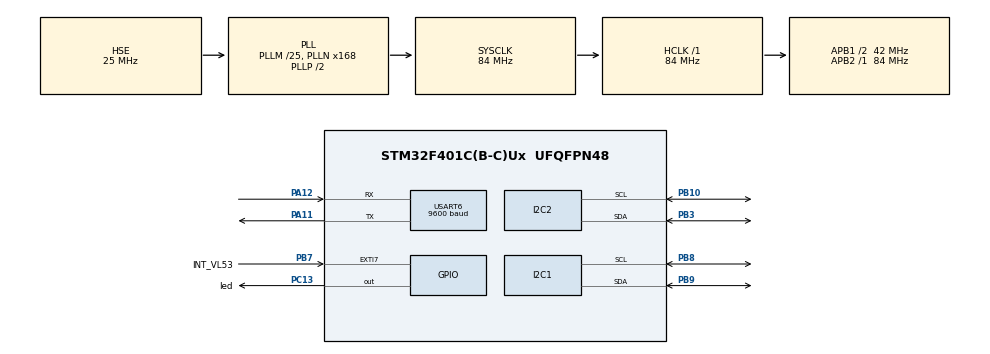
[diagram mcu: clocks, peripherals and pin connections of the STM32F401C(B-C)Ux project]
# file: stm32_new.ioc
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Dma.Request0=USART6_RX
Dma.Request1=USART6_TX
Dma.USART6_RX.0.Direction=DMA_PERIPH_TO_MEMORY
Dma.USART6_RX.0.FIFOMode=DMA_FIFOMODE_DISABLE
Dma.USART6_RX.0.Instance=DMA2_Stream1
Dma.USART6_RX.0.MemDataAlignment=DMA_MDATAALIGN_BYTE
Dma.USART6_RX.0.MemInc=DMA_MINC_ENABLE
Dma.USART6_RX.0.Mode=DMA_NORMAL
Dma.USART6_RX.0.PeriphDataAlignment=DMA_PDATAALIGN_BYTE
Dma.USART6_RX.0.PeriphInc=DMA_PINC_DISABLE
Dma.USART6_RX.0.Priority=DMA_PRIORITY_LOW
Dma.USART6_TX.1.Direction=DMA_MEMORY_TO_PERIPH
Dma.USART6_TX.1.FIFOMode=DMA_FIFOMODE_DISABLE
Dma.USART6_TX.1.Instance=DMA2_Stream6
Dma.USART6_TX.1.MemDataAlignment=DMA_MDATAALIGN_BYTE
Dma.USART6_TX.1.MemInc=DMA_MINC_ENABLE
Dma.USART6_TX.1.Mode=DMA_NORMAL
Dma.USART6_TX.1.PeriphDataAlignment=DMA_PDATAALIGN_BYTE
Dma.USART6_TX.1.PeriphInc=DMA_PINC_DISABLE
Dma.USART6_TX.1.Priority=DMA_PRIORITY_LOW
FREERTOS.Tasks01=VL53_T,24,256,VL53_F,Default,NULL,Dynamic,NULL,NULL;PLC_T,8,256,PLC_F,Default,NULL,Dynamic,NULL,NULL;OLED096_T,8,256,OLED096_F,Default,NULL,Dynamic,NULL,NULL
FREERTOS.configENABLE_FPU=1
FREERTOS.configUSE_NEWLIB_REENTRANT=1
I2C2.I2C_Mode=I2C_Fast
Mcu.Family=STM32F4
Mcu.Name=STM32F401C(B-C)Ux
Mcu.Package=UFQFPN48
NVIC.DMA2_Stream1_IRQn=true\:5\:0\:false\:false\:true\:true\:false\:true\:true
NVIC.DMA2_Stream6_IRQn=true\:5\:0\:false\:false\:true\:true\:false\:true\:true
NVIC.EXTI9_5_IRQn=true\:5\:0\:false\:false\:true\:false\:true\:true\:true
NVIC.PriorityGroup=NVIC_PRIORITYGROUP_4
NVIC.TIM1_BRK_TIM9_IRQn=true\:15\:0\:false\:false\:true\:false\:false\:true\:true
NVIC.TimeBase=TIM1_BRK_TIM9_IRQn
NVIC.TimeBaseIP=TIM9
NVIC.USART6_IRQn=true\:5\:0\:false\:false\:true\:true\:false\:true\:true
PA11.Mode=Asynchronous
PA11.Signal=USART6_TX
PA12.Mode=Asynchronous
PA12.Signal=USART6_RX
PA13.Mode=Serial_Wire
PA13.Signal=SYS_JTMS-SWDIO
PA14.Mode=Serial_Wire
PA14.Signal=SYS_JTCK-SWCLK
PB10.GPIO_Pu=GPIO_PULLUP
PB10.Mode=I2C
PB10.Signal=I2C2_SCL
PB3.GPIO_Pu=GPIO_PULLUP
PB3.Mode=I2C
PB3.Signal=I2C2_SDA
PB7.GPIO_Label=INT_VL53
PB7.GPIO_ModeDefaultEXTI=GPIO_MODE_IT_FALLING
PB7.GPIO_PuPd=GPIO_PULLUP
PB7.Signal=GPXTI7
PB8.Mode=I2C
PB8.Signal=I2C1_SCL
PB9.Mode=I2C
PB9.Signal=I2C1_SDA
PC13-ANTI_TAMP.GPIO_Label=led
PC13-ANTI_TAMP.Signal=GPIO_Output
PH0\ -\ OSC_IN.Mode=HSE-External-Oscillator
PH0\ -\ OSC_IN.Signal=RCC_OSC_IN
PH1\ -\ OSC_OUT.Mode=HSE-External-Oscillator
PH1\ -\ OSC_OUT.Signal=RCC_OSC_OUT
ProjectManager.HeapSize=0x200
ProjectManager.StackSize=0x400
ProjectManager.TargetToolchain=STM32CubeIDE
RCC.48MHZClocksFreq_Value=42000000
RCC.AHBFreq_Value=84000000
RCC.APB1CLKDivider=RCC_HCLK_DIV2
RCC.APB1Freq_Value=42000000
RCC.APB1TimFreq_Value=84000000
RCC.APB2Freq_Value=84000000
RCC.APB2TimFreq_Value=84000000
RCC.CortexFreq_Value=84000000
RCC.HCLKFreq_Value=84000000
RCC.HSE_VALUE=25000000
RCC.HSI_VALUE=16000000
RCC.LSE_VALUE=32768
RCC.PLLM=25
RCC.PLLN=168
RCC.PLLSourceVirtual=RCC_PLLSOURCE_HSE
RCC.SYSCLKFreq_VALUE=84000000
RCC.SYSCLKSource=RCC_SYSCLKSOURCE_PLLCLK
RCC.VCOOutputFreq_Value=168000000
USART6.BaudRate=9600
USART6.OverSampling=UART_OVERSAMPLING_16
USART6.Parity=PARITY_ODD
USART6.VirtualMode=VM_ASYNC
USART6.WordLength=WORDLENGTH_9B
VP_FREERTOS_VS_CMSIS_V2.Mode=CMSIS_V2
VP_SYS_VS_tim9.Mode=TIM9
board=custom

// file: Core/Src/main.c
/* USER CODE BEGIN Header */
/**
  ******************************************************************************
  * @file           : main.c
  * @brief          : Main program body
  ******************************************************************************
  * @attention
  *
  * Copyright (c) 2026 STMicroelectronics.
  * All rights reserved.
  *
  * This software is licensed under terms that can be found in the LICENSE file
  * in the root directory of this software component.
  * If no LICENSE file comes with this software, it is provided AS-IS.
  *
  ******************************************************************************
  */
/* USER CODE END Header */
#include "main.h"
#include "cmsis_os.h"
#include "dma.h"
#include "i2c.h"
#include "usart.h"
#include "gpio.h"

/* USER CODE BEGIN Includes */
#include "VL53L.h"
/* USER CODE END Includes */

void SystemClock_Config(void);
void MX_FREERTOS_Init(void);

int main(void)
{

  /* MCU Configuration--------------------------------------------------------*/

  /* Reset of all peripherals, Initializes the Flash interface and the Systick. */
  HAL_Init();

  /* Configure the system clock */
  SystemClock_Config();

  /* Initialize all configured peripherals */
  MX_GPIO_Init();
  MX_DMA_Init();
  MX_I2C1_Init();
  MX_USART6_UART_Init();
  MX_I2C2_Init();

  /* Init scheduler */
  osKernelInitialize();  /* Call init function for freertos objects (in cmsis_os2.c) */
  MX_FREERTOS_Init();

  /* Start scheduler */
  osKernelStart();

  /* We should never get here as control is now taken by the scheduler */

  /* Infinite loop */
  while (1)
  {

  }
}

void SystemClock_Config(void)
{
  RCC_OscInitTypeDef RCC_OscInitStruct = {0};
  RCC_ClkInitTypeDef RCC_ClkInitStruct = {0};

  /** Configure the main internal regulator output voltage
  */
  __HAL_RCC_PWR_CLK_ENABLE();
  __HAL_PWR_VOLTAGESCALING_CONFIG(PWR_REGULATOR_VOLTAGE_SCALE2);

  /** Initializes the RCC Oscillators according to the specified parameters
  * in the RCC_OscInitTypeDef structure.
  */
  RCC_OscInitStruct.OscillatorType = RCC_OSCILLATORTYPE_HSE;
  RCC_OscInitStruct.HSEState = RCC_HSE_ON;
  RCC_OscInitStruct.PLL.PLLState = RCC_PLL_ON;
  RCC_OscInitStruct.PLL.PLLSource = RCC_PLLSOURCE_HSE;
  RCC_OscInitStruct.PLL.PLLM = 25;
  RCC_OscInitStruct.PLL.PLLN = 168;
  RCC_OscInitStruct.PLL.PLLP = RCC_PLLP_DIV2;
  RCC_OscInitStruct.PLL.PLLQ = 4;
  if (HAL_RCC_OscConfig(&RCC_OscInitStruct) != HAL_OK)
  {
    Error_Handler();
  }

  /** Initializes the CPU, AHB and APB buses clocks
  */
  RCC_ClkInitStruct.ClockType = RCC_CLOCKTYPE_HCLK|RCC_CLOCKTYPE_SYSCLK
                              |RCC_CLOCKTYPE_PCLK1|RCC_CLOCKTYPE_PCLK2;
  RCC_ClkInitStruct.SYSCLKSource = RCC_SYSCLKSOURCE_PLLCLK;
  RCC_ClkInitStruct.AHBCLKDivider = RCC_SYSCLK_DIV1;
  RCC_ClkInitStruct.APB1CLKDivider = RCC_HCLK_DIV2;
  RCC_ClkInitStruct.APB2CLKDivider = RCC_HCLK_DIV1;

  if (HAL_RCC_ClockConfig(&RCC_ClkInitStruct, FLASH_LATENCY_2) != HAL_OK)
  {
    Error_Handler();
  }
}

void HAL_TIM_PeriodElapsedCallback(TIM_HandleTypeDef *htim)
{
  if (htim->Instance == TIM9)
  {
    HAL_IncTick();
  }
}

void Error_Handler(void)
{
  __disable_irq();
  while (1)
  {
  }
}

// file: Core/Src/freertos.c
/* USER CODE BEGIN Header */
/**
  ******************************************************************************
  * File Name          : freertos.c
  * Description        : Code for freertos applications
  ******************************************************************************
  * @attention
  *
  * Copyright (c) 2026 STMicroelectronics.
  * All rights reserved.
  *
  * This software is licensed under terms that can be found in the LICENSE file
  * in the root directory of this software component.
  * If no LICENSE file comes with this software, it is provided AS-IS.
  *
  ******************************************************************************
  */
/* USER CODE END Header */

#include "FreeRTOS.h"
#include "task.h"
#include "main.h"
#include "cmsis_os.h"

/* USER CODE BEGIN Includes */
#include "VL53L.h"
#include "oled_ssd1306.h"
/* USER CODE END Includes */

/* Definitions for VL53_T */
osThreadId_t VL53_THandle;
const osThreadAttr_t VL53_T_attributes = {
  .name = "VL53_T",
  .stack_size = 256 * 4,
  .priority = (osPriority_t) osPriorityNormal,
};
/* Definitions for PLC_T */
osThreadId_t PLC_THandle;
const osThreadAttr_t PLC_T_attributes = {
  .name = "PLC_T",
  .stack_size = 256 * 4,
  .priority = (osPriority_t) osPriorityLow,
};
/* Definitions for OLED096_T */
osThreadId_t OLED096_THandle;
const osThreadAttr_t OLED096_T_attributes = {
  .name = "OLED096_T",
  .stack_size = 256 * 4,
  .priority = (osPriority_t) osPriorityLow,
};

void VL53_F(void *argument);
void PLC_F(void *argument);
void OLED096_F(void *argument);

void MX_FREERTOS_Init(void); /* (MISRA C 2004 rule 8.1) */

void MX_FREERTOS_Init(void) {

  /* Create the thread(s) */
  /* creation of VL53_T */
  VL53_THandle = osThreadNew(VL53_F, NULL, &VL53_T_attributes);

  /* creation of PLC_T */
  PLC_THandle = osThreadNew(PLC_F, NULL, &PLC_T_attributes);

  /* creation of OLED096_T */
  OLED096_THandle = osThreadNew(OLED096_F, NULL, &OLED096_T_attributes);

}

void VL53_F(void *argument)
{
  /* USER CODE BEGIN VL53_F */
  VL53L_Init();

  /* Infinite loop */
  for(;;)
  {
    VL53L_Task_Sensor();
    osDelay(30);
  }
  /* USER CODE END VL53_F */
}

void PLC_F(void *argument)
{
  /* USER CODE BEGIN PLC_F */
  osDelay(500); // Đợi cảm biến và hệ thống ổn định

  /* Infinite loop */
  for(;;)
  {
    VL53L_Task_PLC();
    osDelay(10);
  }
  /* USER CODE END PLC_F */
}

void OLED096_F(void *argument)
{
  /* USER CODE BEGIN OLED096_F */
  osDelay(300); // Đợi OLED và I2C2 ổn định nguồn
  OLED_Init();

  /* Infinite loop */
  for(;;)
  {
    OLED_Task_Run();
    osDelay(100); // Cập nhật màn hình 10 lần/giây
  }
  /* USER CODE END OLED096_F */
}
